# STM32WL5Mxx register map
File version: 1.0
Registers are 32-bit, read-write, reset 0x0 unless marked. A register's access mark holds for its fields unless they carry their own. Offsets are from the block's base; [hi:lo] are bit positions; {n}, {i} and the like mark numbered series; 'fields as' and 'values as' point back to an identical list.

## RCC — Reset and Clock Control
Base 0x58000000
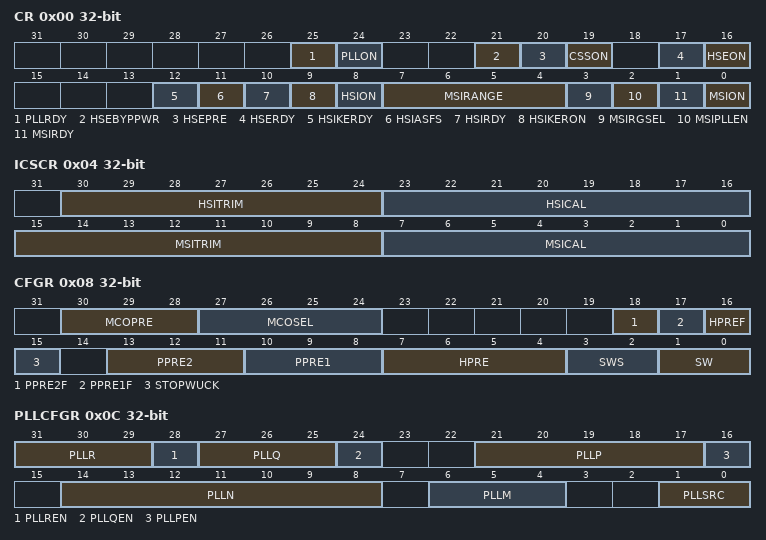
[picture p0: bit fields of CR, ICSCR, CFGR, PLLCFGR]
0x00 CR — RCC clock Control Register
  [25] PLLRDY — System PLL clock ready
  [24] PLLON — System PLL clock enable
  [21] HSEBYPPWR — Enable HSE32 VDDTCXO
  [20] HSEPRE — HSE sysclk prescaler
  [19] CSSON — HSE Clock Security System enable
  [17] HSERDY — External High Speed oscillator (HSE) clock ready
  [16] HSEON — External High Speed oscillator (HSE) clock enable
  [12] HSIKERDY — Internal High Speed oscillator (HSI16) clock enable for some IPs Kernel ready flag
  [11] HSIASFS — HSI16 Automatic Start from Stop
  [10] HSIRDY — Internal High Speed oscillator (HSI16) clock ready flag
  [9] HSIKERON — Internal High Speed oscillator (HSI16) clock enable for some IPs Kernel
  [8] HSION — Internal High Speed oscillator (HSI16) clock enable
  [7:4] MSIRANGE — Internal Multi Speed oscillator (MSI) clock Range
    0=MSI = 100 KHz; 1=MSI = 200 KHz; 2=MSI = 400 KHz; 3=MSI = 800 KHz; 4=MSI = 1 MHz; 5=MSI = 2 MHz; 6=MSI = 4 MHz; 7=MSI = 8 MHz; 8=MSI = 16 MHz; 9=MSI = 24 MHz; 10=MSI = 32 MHz; 11=MSI = 48 MHz
  [3] MSIRGSEL — Internal Multi Speed oscillator (MSI) range selection
  [2] MSIPLLEN — Internal Multi Speed oscillator (MSI) PLL enable
  [1] MSIRDY — Internal Multi Speed oscillator (MSI) clock ready flag
  [0] MSION — Internal Multi Speed oscillator (MSI) clock enable
0x04 ICSCR — RCC Internal Clock Sources Calibration Register
  [30:24] HSITRIM — HSITRIM[6:0] bits
  [23:16] HSICAL — HSICAL[7:0] bits
  [15:8] MSITRIM — MSITRIM[7:0] bits
  [7:0] MSICAL — MSICAL[7:0] bits
0x08 CFGR — RCC Clocks Configuration Register
  [30:28] MCOPRE — MCO prescaler
  [27:24] MCOSEL — MCOSEL [3:0] bits (Clock output selection)
  [18] PPRE2F — APB2 prescaler flag
  [17] PPRE1F — CPU1 APB1 prescaler flag
  [16] HPREF — AHB prescaler flag
  [15] STOPWUCK — Wake Up from stop and CSS backup clock selection
    0=MSI (MSI selection after wake-up from STOP); 1=HSI (HSI selection after wake-up from STOP)
  [13:11] PPRE2 — PRE2[2:0] bits (APB2 prescaler)
    0=DIV_1 (HCLK1 not divided); 4=DIV_2 (HCLK1 divided by 2); 5=DIV_4 (HCLK1 divided by 4); 6=DIV_8 (HCLK1 divided by 8); 7=DIV_16 (HCLK1 divided by 16)
  [10:8] PPRE1 — PRE1[2:0] bits (APB1 prescaler)
    values as PPRE2
  [7:4] HPRE — HPRE[3:0] bits (AHB prescaler)
    0=DIV_1 (SYSCLK not divided); 8=DIV_2 (SYSCLK divided by 2); 1=DIV_3 (SYSCLK divided by 3); 9=DIV_4 (SYSCLK divided by 4); 2=DIV_5 (SYSCLK divided by 5); 5=DIV_6 (SYSCLK divided by 6); 10=DIV_8 (SYSCLK divided by 8); 6=DIV_10 (SYSCLK divided by 10); 11=DIV_16 (SYSCLK divided by 16); 7=DIV_32 (SYSCLK divided by 32); 12=DIV_64 (SYSCLK divided by 64); 13=DIV_128 (SYSCLK divided by 128); 14=DIV_256 (SYSCLK divided by 256); 15=DIV_512 (SYSCLK divided by 512)
  [3:2] SWS — SWS[1:0] bits (System Clock Switch Status)
    0=MSI (MSI used as system clock); 1=HSI (HSI used as system clock); 2=HSE (HSE used as system clock); 3=PLL (PLL used as system clock)
  [1:0] SW — SW[1:0] bits (System clock Switch)
    0=MSI (MSI selection as system clock); 1=HSI (HSI selection as system clock); 2=HSE (HSE selection as system clock); 3=PLL (PLL selection as system clock)
0x0C PLLCFGR — RCC System PLL configuration Register
  [31:29] PLLR
    {v}=DIV_{v+1} (Main PLL division factor for PLLCLK (system clock) by {v+1}) (v=1..7)
  [28] PLLREN
  [27:25] PLLQ
    {v}=DIV_{v+1} (Main PLL division factor for PLLQ output by {v+1}) (v=1..7)
  [24] PLLQEN
  [21:17] PLLP
    {v}=DIV_{v+1} (Main PLL division factor for PLLP output by {v+1}) (v=1..31)
  [16] PLLPEN
  [14:8] PLLN
  [6:4] PLLM
    {v}=DIV_{v+1} (PLL division factor by {v+1}) (v=0..7)
  [1:0] PLLSRC
    1=MSI (MSI clock selected as PLL entry clock source); 2=HSI (HSI clock selected as PLL entry clock source); 3=HSE (HSE clock selected as PLL entry clock source); 0=NONE (No clock)
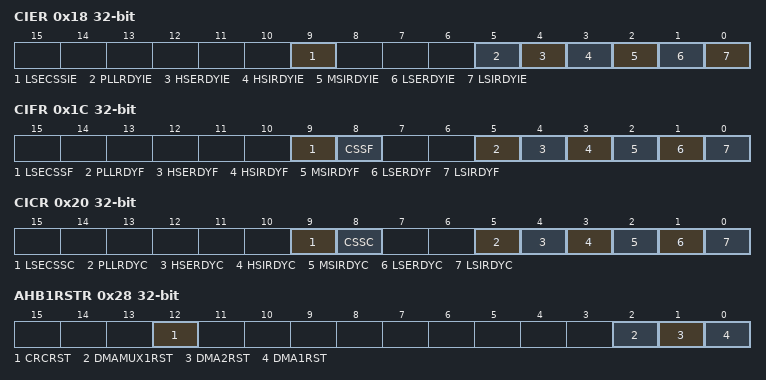
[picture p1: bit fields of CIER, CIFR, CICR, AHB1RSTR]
0x18 CIER — RCC Clock Interrupt Enable Register
  [9] LSECSSIE, [5] PLLRDYIE, [4] HSERDYIE, [3] HSIRDYIE, [2] MSIRDYIE, [1] LSERDYIE, [0] LSIRDYIE
0x1C CIFR — RCC Clock Interrupt Flag Register
  [9] LSECSSF, [8] CSSF, [5] PLLRDYF, [4] HSERDYF, [3] HSIRDYF, [2] MSIRDYF, [1] LSERDYF, [0] LSIRDYF
0x20 CICR — RCC Clock Interrupt Clear Register
  [9] LSECSSC, [8] CSSC, [5] PLLRDYC, [4] HSERDYC, [3] HSIRDYC, [2] MSIRDYC, [1] LSERDYC, [0] LSIRDYC
0x28 AHB1RSTR — RCC AHB1 peripheral reset register
  [12] CRCRST, [2] DMAMUX1RST, [1] DMA2RST, [0] DMA1RST
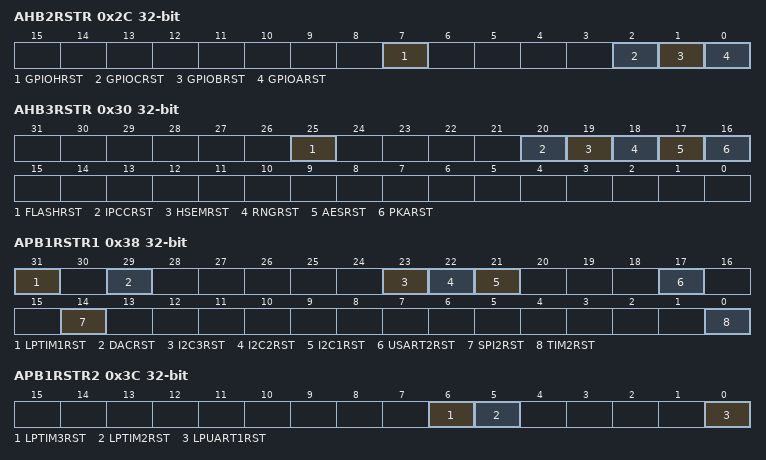
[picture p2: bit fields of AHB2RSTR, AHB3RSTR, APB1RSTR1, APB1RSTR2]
0x2C AHB2RSTR — RCC AHB2 peripheral reset register
  [7] GPIOHRST, [2] GPIOCRST, [1] GPIOBRST, [0] GPIOARST
0x30 AHB3RSTR — RCC AHB3 peripheral reset register
  [25] FLASHRST, [20] IPCCRST, [19] HSEMRST, [18] RNGRST, [17] AESRST, [16] PKARST
0x38 APB1RSTR1 — RCC APB1 peripheral reset register 1
  [31] LPTIM1RST, [29] DACRST, [23] I2C3RST, [22] I2C2RST, [21] I2C1RST, [17] USART2RST, [14] SPI2RST, [0] TIM2RST
0x3C APB1RSTR2 — RCC APB1 peripheral reset register 2
  [6] LPTIM3RST, [5] LPTIM2RST, [0] LPUART1RST
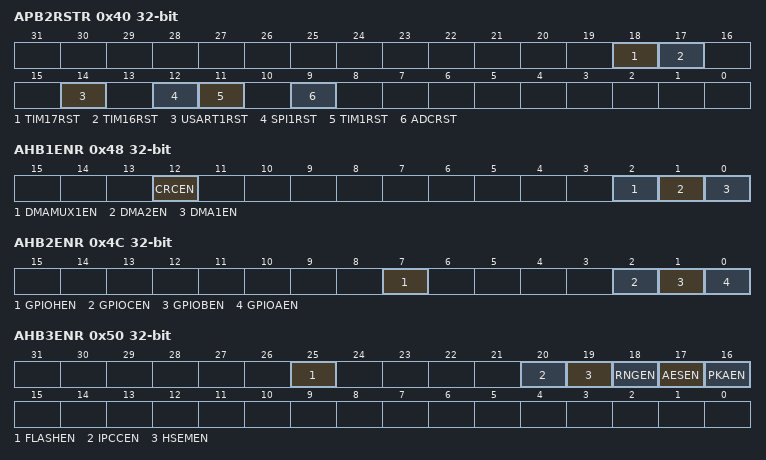
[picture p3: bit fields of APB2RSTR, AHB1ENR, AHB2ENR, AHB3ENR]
0x40 APB2RSTR — RCC APB2 peripheral reset register
  [18] TIM17RST, [17] TIM16RST, [14] USART1RST, [12] SPI1RST, [11] TIM1RST, [9] ADCRST
0x44 APB3RSTR — RCC APB3 peripheral reset register
  [0] SUBGHZSPIRST
0x48 AHB1ENR — RCC AHB1 peripheral clocks enable register
  [12] CRCEN, [2] DMAMUX1EN, [1] DMA2EN, [0] DMA1EN
0x4C AHB2ENR — RCC AHB2 peripheral clocks enable register
  [7] GPIOHEN, [2] GPIOCEN, [1] GPIOBEN, [0] GPIOAEN
0x50 AHB3ENR — RCC AHB3 peripheral clocks enable register
  [25] FLASHEN, [20] IPCCEN, [19] HSEMEN, [18] RNGEN, [17] AESEN, [16] PKAEN
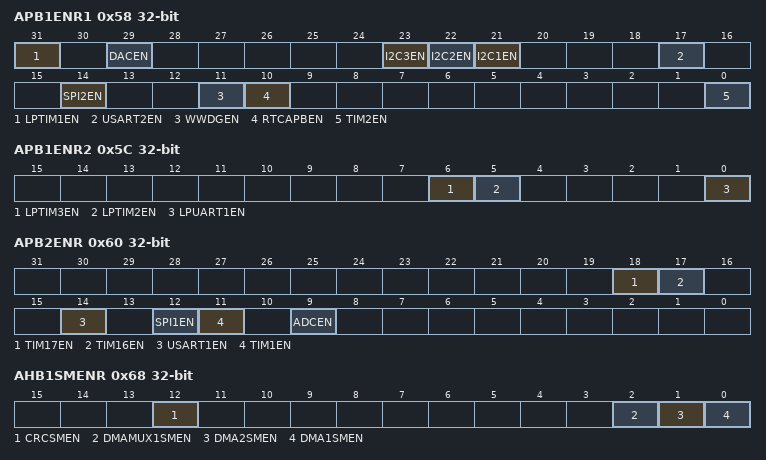
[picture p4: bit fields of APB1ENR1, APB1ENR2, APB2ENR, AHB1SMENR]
0x58 APB1ENR1 — RCC APB1 peripheral clocks enable register 1
  [31] LPTIM1EN, [29] DACEN, [23] I2C3EN, [22] I2C2EN, [21] I2C1EN, [17] USART2EN, [14] SPI2EN, [11] WWDGEN, [10] RTCAPBEN, [0] TIM2EN
0x5C APB1ENR2 — RCC APB1 peripheral clocks enable register 2
  [6] LPTIM3EN, [5] LPTIM2EN, [0] LPUART1EN
0x60 APB2ENR — RCC APB2 peripheral clocks enable register
  [18] TIM17EN, [17] TIM16EN, [14] USART1EN, [12] SPI1EN, [11] TIM1EN, [9] ADCEN
0x64 APB3ENR — RCC APB3 peripheral clocks enable register
  [0] SUBGHZSPIEN
0x68 AHB1SMENR — RCC AHB1 peripheral clocks enable in sleep and stop modes register
  [12] CRCSMEN, [2] DMAMUX1SMEN, [1] DMA2SMEN, [0] DMA1SMEN
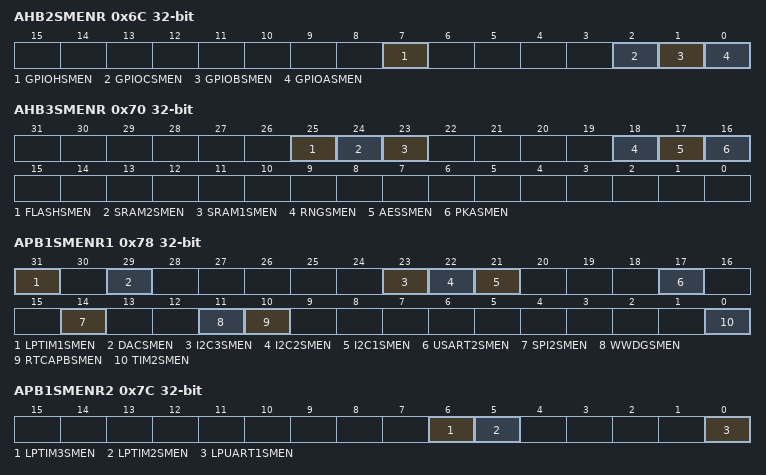
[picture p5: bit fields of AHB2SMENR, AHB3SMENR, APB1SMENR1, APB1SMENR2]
0x6C AHB2SMENR — RCC AHB2 peripheral clocks enable in sleep and stop modes register
  [7] GPIOHSMEN, [2] GPIOCSMEN, [1] GPIOBSMEN, [0] GPIOASMEN
0x70 AHB3SMENR — RCC AHB3 & AHB4 peripheral clocks enable in sleep and stop modes register
  [25] FLASHSMEN, [24] SRAM2SMEN, [23] SRAM1SMEN, [18] RNGSMEN, [17] AESSMEN, [16] PKASMEN
0x78 APB1SMENR1 — RCC APB1 peripheral clocks enable in sleep mode and stop modes register 1
  [31] LPTIM1SMEN, [29] DACSMEN, [23] I2C3SMEN, [22] I2C2SMEN, [21] I2C1SMEN, [17] USART2SMEN, [14] SPI2SMEN, [11] WWDGSMEN, [10] RTCAPBSMEN, [0] TIM2SMEN
0x7C APB1SMENR2 — RCC APB1 peripheral clocks enable in sleep mode and stop modes register 2
  [6] LPTIM3SMEN, [5] LPTIM2SMEN, [0] LPUART1SMEN
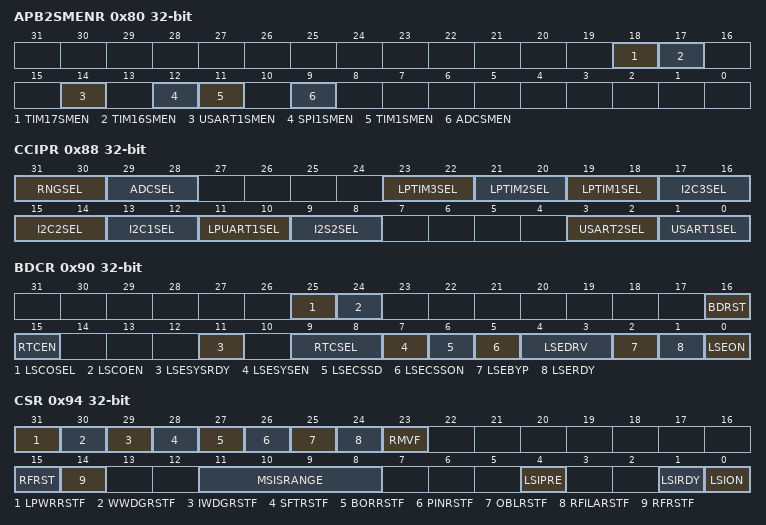
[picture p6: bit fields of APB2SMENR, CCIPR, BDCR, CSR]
0x80 APB2SMENR — RCC APB2 peripheral clocks enable in sleep mode and stop modes register
  [18] TIM17SMEN, [17] TIM16SMEN, [14] USART1SMEN, [12] SPI1SMEN, [11] TIM1SMEN, [9] ADCSMEN
0x84 APB3SMENR — RCC APB3 peripheral clocks enable in sleep mode and stop modes register
  [0] SUBGHZSPISMEN
0x88 CCIPR — RCC Peripherals Clock Configuration Independent Register
  [31:30] RNGSEL
    0=PLL (PLL selected as RNG Clock); 1=LSI (LSI selected as RNG clock); 2=LSE (LSE selected as RNG clock); 3=MSI (MSI selected as RNG clock)
  [29:28] ADCSEL
    0=NONE (no Clock used as ADC clock); 2=PLL (PLL selected as ADC clock); 3=SYSCLK (SYSCLK selected as ADC clock)
  [23:22] LPTIM3SEL
  [21:20] LPTIM2SEL
  [19:18] LPTIM1SEL
  [17:16] I2C3SEL
  [15:14] I2C2SEL
  [13:12] I2C1SEL
  [11:10] LPUART1SEL
    0=PCLK1 (PCLK1 selected as LPUART1 clock); 1=SYSCLK (SYCLK selected as LPUART1 clock); 2=HSI (HSI selected as LPUART1 clock); 3=LSE (LSE selected as LPUART1 clock)
  [9:8] I2S2SEL
    1=PLL (PLL clock used as I2S2 clock source); 2=HSI (HSI clock used as I2S2 clock source); 3=PIN (External clock used as I2S2 clock source)
  [3:2] USART2SEL
  [1:0] USART1SEL
0x90 BDCR — RCC Backup Domain Control Register
  [25] LSCOSEL
    0=LSI (LSI selection for low speed clock); 1=LSE (LSE selection for low speed clock)
  [24] LSCOEN
  [16] BDRST
  [15] RTCEN
  [11] LSESYSRDY
  [9:8] RTCSEL
    0=NONE (No clock used as RTC clock); 1=LSE (LSE oscillator clock used as RTC clock); 2=LSI (LSI oscillator clock used as RTC clock); 3=HSE_DIV32 (HSE oscillator clock divided by 32 used as RTC clock)
  [7] LSESYSEN
  [6] LSECSSD
  [5] LSECSSON
  [4:3] LSEDRV
    0=LOW (Xtal mode lower driving capability); 1=MEDIUMLOW (Xtal mode medium low driving capability); 2=MEDIUMHIGH (Xtal mode medium high driving capability); 3=HIGH (Xtal mode higher driving capability)
  [2] LSEBYP
  [1] LSERDY
  [0] LSEON
0x94 CSR — RCC Control and Status Register
  [31] LPWRRSTF
  [30] WWDGRSTF
  [29] IWDGRSTF
  [28] SFTRSTF
  [27] BORRSTF
  [26] PINRSTF
  [25] OBLRSTF
  [24] RFILARSTF
  [23] RMVF
  [15] RFRST
  [14] RFRSTF
  [11:8] MSISRANGE
    4=MSI = 1 MHz; 5=MSI = 2 MHz; 6=MSI = 4 MHz; 7=MSI = 8 MHz
  [4] LSIPRE
    0=PREDIV_1 (LSI division factor by 1); 1=PREDIV_128 (LSI division factor by 128)
  [1] LSIRDY
  [0] LSION
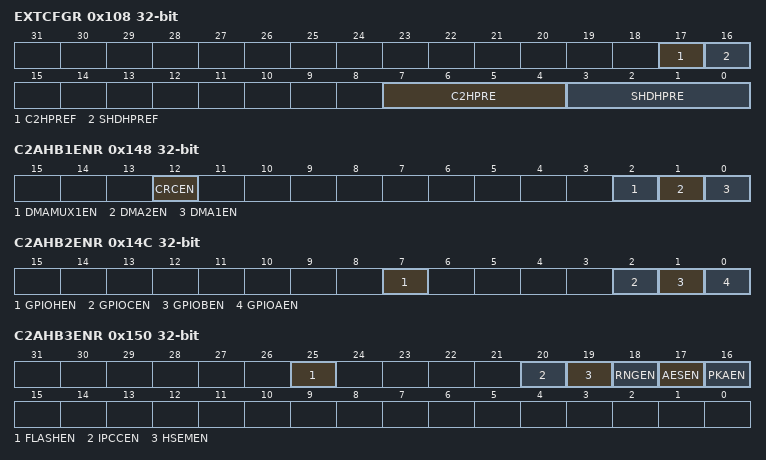
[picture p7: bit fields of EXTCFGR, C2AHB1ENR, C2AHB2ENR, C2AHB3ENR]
0x108 EXTCFGR — RCC Extended Clock Recovery Register
  [17] C2HPREF
  [16] SHDHPREF
  [7:4] C2HPRE
    values as CFGR.HPRE
  [3:0] SHDHPRE
0x148 C2AHB1ENR — RRCC AHB1 peripheral CPU2 clocks enable register
  [12] CRCEN, [2] DMAMUX1EN, [1] DMA2EN, [0] DMA1EN
0x14C C2AHB2ENR — RCC AHB2 peripheral CPU2 clocks enable register
  [7] GPIOHEN, [2] GPIOCEN, [1] GPIOBEN, [0] GPIOAEN
0x150 C2AHB3ENR — RCC AHB3 & AHB4 peripheral CPU2 clocks enable register
  fields as AHB3ENR
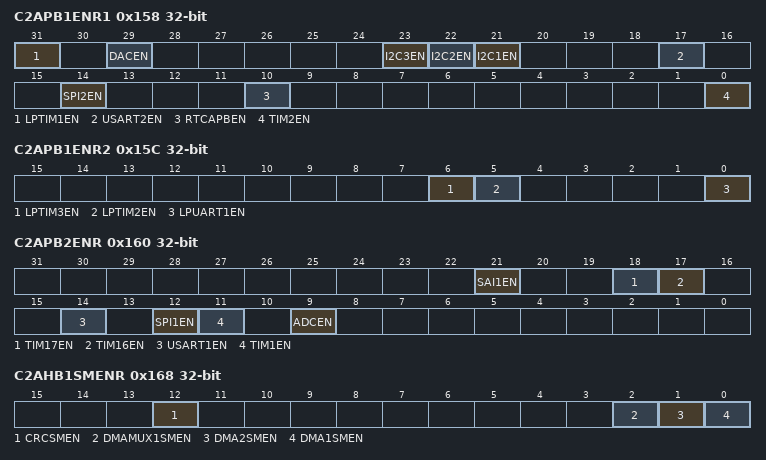
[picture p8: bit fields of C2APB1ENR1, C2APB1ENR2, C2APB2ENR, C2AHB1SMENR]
0x158 C2APB1ENR1 — RCC APB1 peripheral CPU2 clocks enable register 1
  [31] LPTIM1EN, [29] DACEN, [23] I2C3EN, [22] I2C2EN, [21] I2C1EN, [17] USART2EN, [14] SPI2EN, [10] RTCAPBEN, [0] TIM2EN
0x15C C2APB1ENR2 — RCC APB1 peripheral CPU2 clocks enable register 2
  [6] LPTIM3EN, [5] LPTIM2EN, [0] LPUART1EN
0x160 C2APB2ENR — RCC APB2 peripheral CPU2 clocks enable register 1
  [21] SAI1EN, [18] TIM17EN, [17] TIM16EN, [14] USART1EN, [12] SPI1EN, [11] TIM1EN, [9] ADCEN
0x164 C2APB3ENR — RCC APB3 peripheral CPU2 clocks enable register 1
  [0] SUBGHZSPIEN
0x168 C2AHB1SMENR — RCC AHB1 peripheral CPU2 clocks enable in sleep and stop modes register
  [12] CRCSMEN, [2] DMAMUX1SMEN, [1] DMA2SMEN, [0] DMA1SMEN
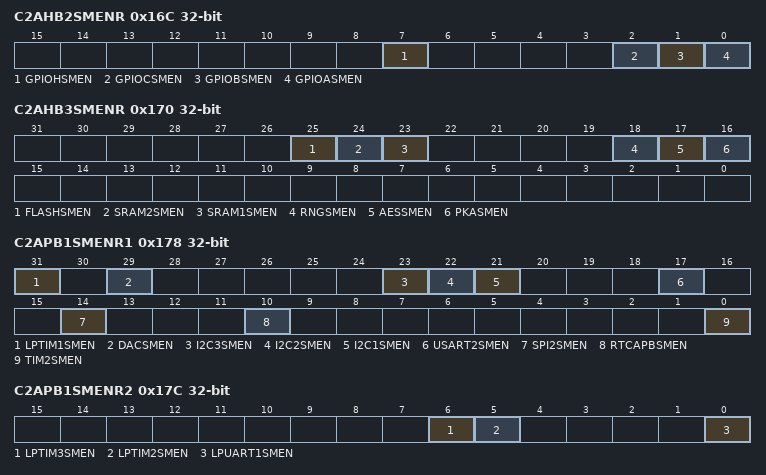
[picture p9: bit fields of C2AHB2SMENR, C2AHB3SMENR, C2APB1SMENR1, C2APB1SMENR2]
0x16C C2AHB2SMENR — RCC AHB2 peripheral CPU2 clocks enable in sleep and stop modes register
  [7] GPIOHSMEN, [2] GPIOCSMEN, [1] GPIOBSMEN, [0] GPIOASMEN
0x170 C2AHB3SMENR — RCC AHB3 & AHB4 peripheral CPU2 clocks enable in sleep and stop modes register
  fields as AHB3SMENR
0x178 C2APB1SMENR1 — RCC APB1 peripheral CPU2 clocks enable in sleep mode and stop modes register 1
  [31] LPTIM1SMEN, [29] DACSMEN, [23] I2C3SMEN, [22] I2C2SMEN, [21] I2C1SMEN, [17] USART2SMEN, [14] SPI2SMEN, [10] RTCAPBSMEN, [0] TIM2SMEN
0x17C C2APB1SMENR2 — RCC APB1 peripheral CPU2 clocks enable in sleep mode and stop modes register 2
  [6] LPTIM3SMEN, [5] LPTIM2SMEN, [0] LPUART1SMEN
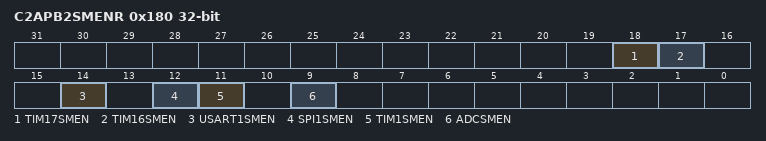
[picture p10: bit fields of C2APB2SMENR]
0x180 C2APB2SMENR — RCC APB2 peripheral CPU2 clocks enable in sleep mode and stop modes register
  fields as APB2SMENR
0x184 C2APB3SMENR — RCC APB3 peripheral CPU2 clocks enable in sleep mode and stop modes register
  [0] SUBGHZSPISMEN
